# f29h85x_dlt_core_regs register map
Vendor: Texas Instruments
Peripheral module from a debugger description file (folder C29).
Registers are 32-bit, read-write, no defined reset value unless marked. A register's access mark holds for its fields unless they carry their own. Offsets are as the file gives them; lines under a group give offsets from that group; [hi:lo] are bit positions; {n}, {i} and the like mark numbered series; 'fields as' and 'values as' point back to an identical list; <NAME> marks a mode.

## DLT_CORE_REGS — DLT CORE Registers
0x00 ERAD_START_MASK_L — ERAD Start Mask for Lower 32 lines
  [31:0] START_MASK — Mask for first 32 ERAD events
0x04 ERAD_START_MASK_H — ERAD Start Mask for Higher 32 lines
  [31:0] START_MASK — Mask for last 32 ERAD events
0x08 ERAD_END_MASK_L — ERAD End Mask for Lower 32 lines
  [31:0] END_MASK — Mask for first 32 ERAD events
0x0C ERAD_END_MASK_H — ERAD End Mask for Higher 32 lines
  [31:0] END_MASK — Mask for last 32 ERAD events
0x10 TAG_FILTER_START_REF — Tag Filer Start Reference
  [15:0] START_REF — Reference for TAG start comparison
0x14 TAG_FILTER_START_MASK — Tag Filer Start Mask
  [15:0] START_MASK — MASK for TAG start comparison
0x18 TAG_FILTER_END_REF — Tag Filer End Reference
  [15:0] END_REF — Reference for TAG end comparison
0x1C TAG_FILTER_END_MASK — Tag Filer End Mask
  [15:0] END_MASK — MASK for TAG end comparison
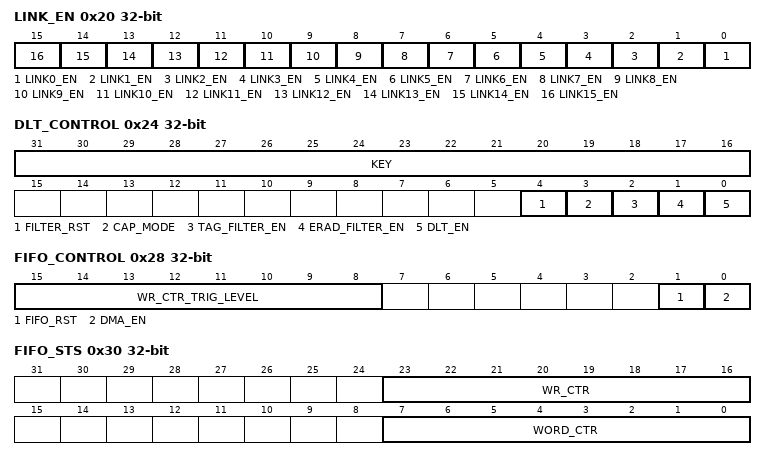
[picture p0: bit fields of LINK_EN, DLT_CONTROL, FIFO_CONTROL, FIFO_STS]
0x20 LINK_EN — Link Enable
  [n] LINK{n}_EN (n=0..15) — LINK permissions to write to FIFO
0x24 DLT_CONTROL
  [31:16] KEY — key to enable write to lower [15:0] bit fileds
  [4] FILTER_RST — Filter Reset
  [3] CAP_MODE — Capture mode
  [2] TAG_FILTER_EN — TAG Filter Enable
  [1] ERAD_FILTER_EN — ERAD Filter Enable
  [0] DLT_EN — DLTAG Enable
0x28 FIFO_CONTROL
  [15:8] WR_CTR_TRIG_LEVEL — Level of FIFO writes required to trigger INT/DMA
  [1] FIFO_RST — Initialize pointers of FIFO to 0
  [0] DMA_EN — Trigger DMA on FIFO level
0x2C TIMER_CONTROL
  [1] TIMER2_RST — Timer 2 is reset
0x30 FIFO_STS ro — Number of entries in FIFO
  [23:16] WR_CTR — Write counter of FIFO after last trigger
  [7:0] WORD_CTR — Number of 64-bit words to be read in the FIFO
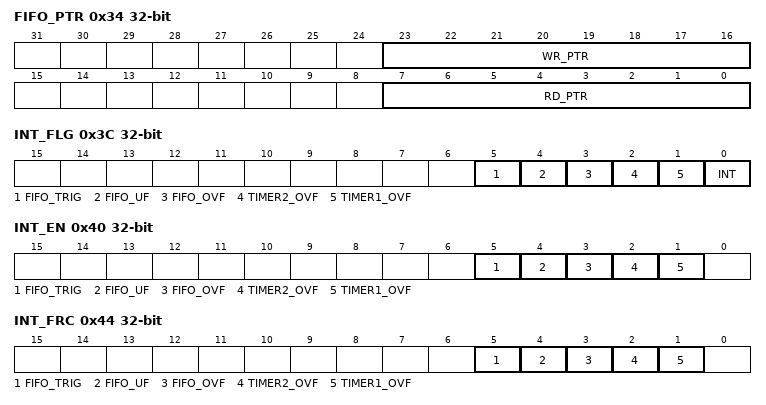
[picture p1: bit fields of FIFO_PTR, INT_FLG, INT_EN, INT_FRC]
0x34 FIFO_PTR ro — Pointer locations in FIFO
  [23:16] WR_PTR — Write pointer location of FIFO
  [7:0] RD_PTR — Read pointer location of FIFO
0x38 TIMER2_COUNT ro — Timer2 Status
  [28:0] COUNT — Current value of TIMER2
0x3C INT_FLG ro — Interrupt Flag
  [5] FIFO_TRIG — FIFO reached Trigger level status
  [4] FIFO_UF — FIFO underflow status
  [3] FIFO_OVF — FIFO overflow status
  [2] TIMER2_OVF — TIMER2 overflow status
  [1] TIMER1_OVF — TIMER1 overflow status
  [0] INT — Global Interrupt Status
0x40 INT_EN — Interrupt Enable
  [5] FIFO_TRIG — FIFO reached Trigger level enable
  [4] FIFO_UF — FIFO underflow enable
  [3] FIFO_OVF — FIFO overflow enable
  [2] TIMER2_OVF — TIMER2 overflow enable
  [1] TIMER1_OVF — TIMER1 overflow enable
0x44 INT_FRC — Interrupt Force
  [5] FIFO_TRIG — FIFO reached Trigger level force
  [4] FIFO_UF — FIFO underflow force
  [3] FIFO_OVF — FIFO overflow force
  [2] TIMER2_OVF — TIMER2 overflow force
  [1] TIMER1_OVF — TIMER1 overflow force
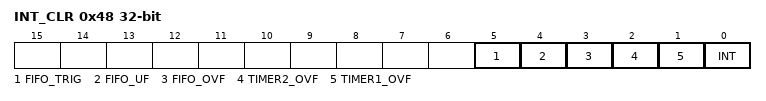
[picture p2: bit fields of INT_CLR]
0x48 INT_CLR — Interrupt Clear
  [5] FIFO_TRIG — FIFO reached Trigger level clear
  [4] FIFO_UF — FIFO underflow clear
  [3] FIFO_OVF — FIFO overflow clear
  [2] TIMER2_OVF — TIMER2 overflow clear
  [1] TIMER1_OVF — TIMER1 overflow clear
  [0] INT — Global Interrupt clear
